# RasbperryPi register map
File version: 1
Registers are 32-bit, read-write, reset 0x0 unless marked. A register's access mark holds for its fields unless they carry their own. Offsets are from the block's base; [hi:lo] are bit positions; {n}, {i} and the like mark numbered series; 'fields as' and 'values as' point back to an identical list.

## CM — Derived from cpr_clkman.h password: 0x5A000000 apb_id: 0x0000636D
Base 0x7E101000
0x00 GNRICCTL 20-bit
  [19:12] _, [11] FLIP, [10:9] MASH, [8] BUSYD, [7] BUSY, [6] GATE, [5] KILL, [4] ENAB, [3:0] SRC
0x00 OSCCOUNT 24-bit
  [23:0] NUM
0x04 GNRICDIV 24-bit
  [23:0] DIV
0x04 PLLA 10-bit
  [9] DIGRST, [8] ANARST, [7] HOLDPER, [6] LOADPER, [5] HOLDCORE, [4] LOADCORE, [3] HOLDCCP2, [2] LOADCCP2, [1] HOLDDSI0, [0] LOADDSI0
0x08 VPUCTL 10-bit reset 0x41
  [9] FRAC, [8] BUSYD, [7] BUSY, [6] GATE, [5:4] _, [3:0] SRC
0x08 PLLC 10-bit
  [9] DIGRST, [8] ANARST, [7] HOLDPER, [6] LOADPER, [5] HOLDCORE2, [4] LOADCORE2, [3] HOLDCORE1, [2] LOADCORE1, [1] HOLDCORE0, [0] LOADCORE0
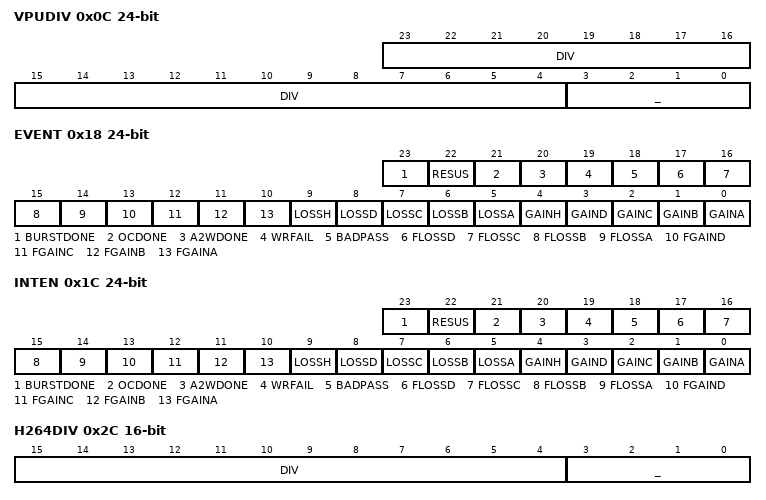
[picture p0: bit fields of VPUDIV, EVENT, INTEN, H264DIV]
0x0C VPUDIV 24-bit
  [23:4] DIV, [3:0] _
0x0C PLLD 10-bit
  [9] DIGRST, [8] ANARST, [7] HOLDPER, [6] LOADPER, [5] HOLDCORE, [4] LOADCORE, [3] HOLDDSI1, [2] LOADDSI1, [1] HOLDDSI0, [0] LOADDSI0
0x10 SYSCTL 7-bit reset 0x40
  [6] GATE, [5:0] _
0x10 PLLH 10-bit
  [9] DIGRST, [8] ANARST, [7:3] _, [2] LOADRCAL, [1] LOADAUX, [0] LOADPIX
0x14 SYSDIV 13-bit ro
  [12] DIV, [11:0] _
0x14 LOCK 13-bit
  [12] FLOCKH, [11] FLOCKD, [10] FLOCKC, [9] FLOCKB, [8] FLOCKA, [7:5] _, [4] LOCKH, [3] LOCKD, [2] LOCKC, [1] LOCKB, [0] LOCKA
0x18 PERIACTL 7-bit reset 0x40
  [6] GATE, [5:0] _
0x18 EVENT 24-bit
  [23] BURSTDONE, [22] RESUS, [21] OCDONE, [20] A2WDONE, [19] WRFAIL, [18] BADPASS, [17] FLOSSD, [16] FLOSSC, [15] FLOSSB, [14] FLOSSA, [13] FGAIND, [12] FGAINC, [11] FGAINB, [10] FGAINA, [9] LOSSH, [8] LOSSD, [7] LOSSC, [6] LOSSB, [5] LOSSA, [4] GAINH, [3] GAIND, [2] GAINC, [1] GAINB, [0] GAINA
0x1C PERIADIV 13-bit ro
  [12] DIV, [11:0] _
0x1C INTEN 24-bit
  fields as EVENT
0x20 PERIICTL 7-bit
  [6] GATE, [5:0] _
0x20 DSI0HSCK 1-bit
  [0] SELPLLD
0x24 PERIIDIV 13-bit ro
  [12] DIV, [11:0] _
0x24 CKSM 22-bit
  [21] STEP, [20] AUTO, [19:18] OSC, [17:16] CFG, [15:8] FRCE, [7:0] STATE
0x28 H264CTL 10-bit reset 0x40
  [9] FRAC, [8] BUSYD, [7] BUSY, [6] GATE, [5] KILL, [4] ENAB, [3:0] SRC
0x28 OSCFREQI 8-bit
  [7:0] INT
0x2C H264DIV 16-bit
  [15:4] DIV, [3:0] _
0x2C OSCFREQF 20-bit
  [19:0] FRAC
0x30 ISPCTL 10-bit reset 0x40
  fields as H264CTL
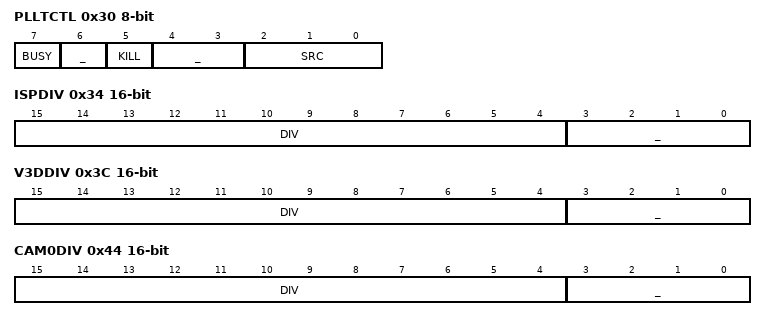
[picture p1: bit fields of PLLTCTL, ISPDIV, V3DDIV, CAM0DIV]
0x30 PLLTCTL 8-bit
  [7] BUSY, [6] _, [5] KILL, [4:3] _, [2:0] SRC
0x34 ISPDIV 16-bit
  [15:4] DIV, [3:0] _
{0x34+4i} PLLTCNT{i} 24-bit (i=0..3)
  [23:0] CNT
0x38 V3DCTL 10-bit reset 0x40
  fields as H264CTL
0x3C V3DDIV 16-bit
  [15:4] DIV, [3:0] _
0x40 CAM0CTL 10-bit
  [9] FRAC, [8] BUSYD, [7] BUSY, [6] _, [5] KILL, [4] ENAB, [3:0] SRC
0x44 CAM0DIV 16-bit
  [15:4] DIV, [3:0] _
0x44 TDCLKEN 14-bit
  [13] IMAGETD, [12] SLIMDFT, [11] USBDFT, [10] MPHIRDFT, [9] MPHIWDFT, [8] HDMIBYP, [7] PLLDDIV2, [6] PLLCDIV2, [5] PLLBDIV2, [4] PLLADIV2, [3] PLLDBYP, [2] PLLCBYP, [1] PLLBBYP, [0] PLLABYP
0x48 CAM1CTL 10-bit
  [9] FRAC, [8] BUSYD, [7] BUSY, [6] _, [5] KILL, [4] ENAB, [3:0] SRC
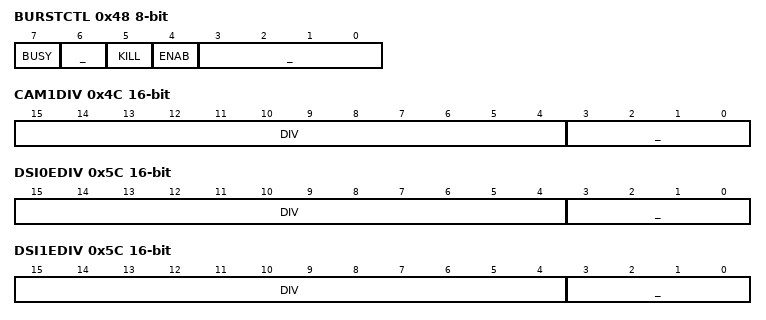
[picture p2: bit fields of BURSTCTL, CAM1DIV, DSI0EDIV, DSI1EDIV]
0x48 BURSTCTL 8-bit
  [7] BUSY, [6] _, [5] KILL, [4] ENAB, [3:0] _
0x4C CAM1DIV 16-bit
  [15:4] DIV, [3:0] _
0x4C BURSTCNT 24-bit
  [23:0] CNT
0x50 CCP2CTL 10-bit
  [9] FRAC, [8] BUSYD, [7] BUSY, [6:5] _, [4] ENAB, [3] _, [2:0] SRC
0x54 CCP2DIV 13-bit ro
  [12] DIV, [11:0] _
0x58 DSI0ECTL 10-bit
  [9] FRAC, [8] BUSYD, [7] BUSY, [6] _, [5] KILL, [4] ENAB, [3:0] SRC
0x58 DSI1ECTL 10-bit
  [9] FRAC, [8] BUSYD, [7] BUSY, [6] _, [5] KILL, [4] ENAB, [3:0] SRC
0x5C DSI0EDIV 16-bit
  [15:4] DIV, [3:0] _
0x5C DSI1EDIV 16-bit
  [15:4] DIV, [3:0] _
0x60 DSI0PCTL 10-bit
  [9] FRAC, [8] BUSYD, [7] BUSY, [6:5] _, [4] ENAB, [3:0] SRC
0x60 DSI1PCTL 10-bit
  [9] FRAC, [8] BUSYD, [7] BUSY, [6:5] _, [4] ENAB, [3:0] SRC
0x64 DSI0PDIV 13-bit ro
  [12] DIV, [11:0] _
0x64 DSI1PDIV 13-bit ro
  [12] DIV, [11:0] _
0x68 DPICTL 10-bit
  [9] FRAC, [8] BUSYD, [7] BUSY, [6] _, [5] KILL, [4] ENAB, [3:0] SRC
0x68 DFTCTL 10-bit
  [9] FRAC, [8] BUSYD, [7] BUSY, [6] _, [5] KILL, [4] ENAB, [3:0] SRC
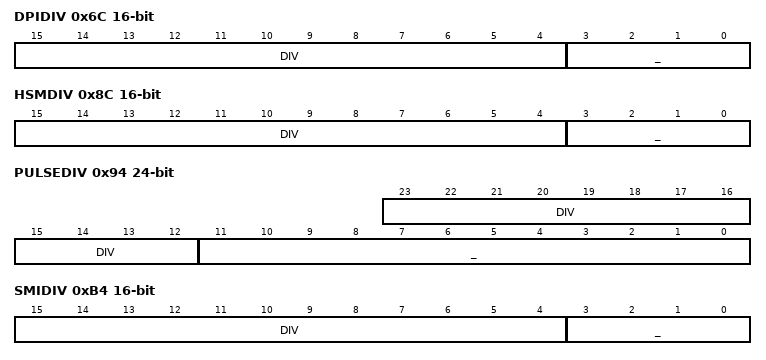
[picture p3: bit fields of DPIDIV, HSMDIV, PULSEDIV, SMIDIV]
0x6C DPIDIV 16-bit
  [15:4] DIV, [3:0] _
0x6C DFTDIV 17-bit
  [16:12] DIV, [11:0] _
0x70 GP0CTL 11-bit
  [10:9] MASH, [8] BUSYD, [7] BUSY, [6] _, [5] KILL, [4] ENAB, [3:0] SRC
0x70 PLLB 10-bit
  [9] DIGRST, [8] ANARST, [7:2] _, [1] HOLDARM, [0] LOADARM
{0x74+8i} GP{i}DIV 24-bit (i=0..2)
  [23:0] DIV
0x78 GP1CTL 11-bit
  fields as GP0CTL
0x80 GP2CTL 10-bit
  [9] FRAC, [8] BUSYD, [7] BUSY, [6] _, [5] KILL, [4] ENAB, [3:0] SRC
0x88 HSMCTL 10-bit
  fields as H264CTL
0x8C HSMDIV 16-bit
  [15:4] DIV, [3:0] _
0x90 OTPCTL 10-bit reset 0x11
  [9] FRAC, [8] BUSYD, [7] BUSY, [6] _, [5] KILL, [4] ENAB, [3:2] _, [1:0] SRC
0x90 PULSECTL 10-bit reset 0x11
  fields as OTPCTL
0x94 OTPDIV 17-bit
  [16:12] DIV, [11:0] _
0x94 PULSEDIV 24-bit
  [23:12] DIV, [11:0] _
0x98 PCMCTL 11-bit
  fields as GP0CTL
0x9C PCMDIV 24-bit
  [23:0] DIV
0xA0 PWMCTL 11-bit
  fields as GP0CTL
0xA4 PWMDIV 24-bit
  [23:0] DIV
0xA8 SDCCTL 18-bit
  [17] UPDATE, [16] ACCPT, [15:12] CTRL, [11:10] _, [9] FRAC, [8] BUSYD, [7] BUSY, [6] _, [5] KILL, [4] ENAB, [3:0] SRC
0xA8 SLIMCTL 11-bit
  fields as GP0CTL
0xAC SDCDIV 18-bit
  [17:12] DIV, [11:0] _
0xAC SLIMDIV 24-bit
  [23:0] DIV
0xB0 ARMCTL 13-bit reset 0x4
  [12] AXIHALF, [11:10] _, [9] FRAC, [8] BUSYD, [7] BUSY, [6] _, [5] KILL, [4] ENAB, [3:0] SRC
0xB0 SMICTL 10-bit
  [9] FRAC, [8] BUSYD, [7] BUSY, [6] _, [5] KILL, [4] ENAB, [3:0] SRC
0xB4 ARMDIV 13-bit ro
  [12] DIV, [11:0] _
0xB4 SMIDIV 16-bit
  [15:4] DIV, [3:0] _
0xB8 AVEOCTL 10-bit
  [9] FRAC, [8] BUSYD, [7] BUSY, [6] _, [5] KILL, [4] ENAB, [3:0] SRC
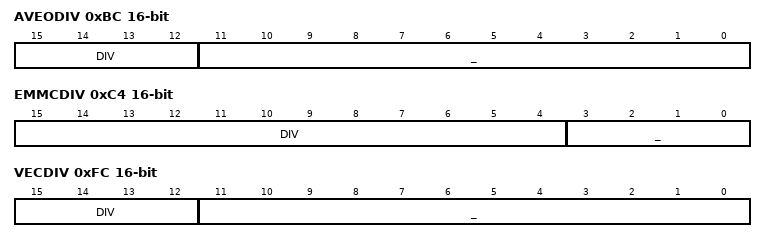
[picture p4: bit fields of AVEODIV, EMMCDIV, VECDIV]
0xBC AVEODIV 16-bit
  [15:12] DIV, [11:0] _
0xC0 TCNTCTL 14-bit
  [13:12] SRC1, [11:8] _, [7] BUSY, [6] KILL, [5:4] _, [3:0] SRC0
0xC0 EMMCCTL 10-bit
  [9] FRAC, [8] BUSYD, [7] BUSY, [6] _, [5] KILL, [4] ENAB, [3:0] SRC
0xC4 TCNTCNT 24-bit
  [23:0] CNT
0xC4 EMMCDIV 16-bit
  [15:4] DIV, [3:0] _
0xC8 TECCTL 10-bit
  fields as OTPCTL
0xCC TECDIV 18-bit
  [17:12] DIV, [11:0] _
0xD0 TD0CTL 13-bit
  [12] STEP, [11] FLIP, [10] _, [9] FRAC, [8] BUSYD, [7] BUSY, [6] GATE, [5] KILL, [4] ENAB, [3:0] SRC
0xD4 TD0DIV 24-bit
  [23:0] DIV
0xD8 TD1CTL 13-bit
  fields as TD0CTL
0xDC TD1DIV 24-bit
  [23:0] DIV
0xE0 TSENSCTL 10-bit
  fields as OTPCTL
0xE4 TSENSDIV 17-bit
  [16:12] DIV, [11:0] _
0xE8 TIMERCTL 10-bit
  fields as OTPCTL
0xEC TIMERDIV 18-bit
  [17:0] DIV
0xF0 UARTCTL 10-bit
  [9] FRAC, [8] BUSYD, [7] BUSY, [6] _, [5] KILL, [4] ENAB, [3:0] SRC
0xF4 UARTDIV 22-bit
  [21:0] DIV
0xF8 VECCTL 10-bit
  [9] FRAC, [8] BUSYD, [7] BUSY, [6] _, [5] KILL, [4] ENAB, [3:0] SRC
0xFC VECDIV 16-bit
  [15:12] DIV, [11:0] _
